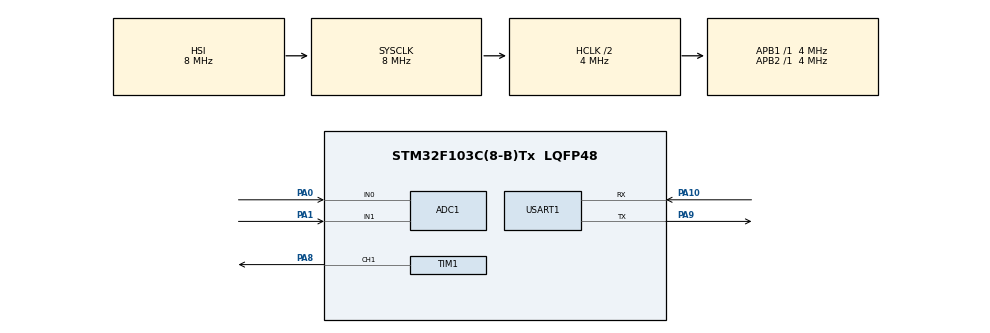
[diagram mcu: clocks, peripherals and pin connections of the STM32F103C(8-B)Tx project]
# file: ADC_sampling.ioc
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ADC1.Channel-7\#ChannelRegularConversion=ADC_CHANNEL_0
ADC1.Channel-8\#ChannelRegularConversion=ADC_CHANNEL_1
ADC1.Channel-9\#ChannelRegularConversion=ADC_CHANNEL_VREFINT
ADC1.ContinuousConvMode=DISABLE
ADC1.DataAlign=ADC_DATAALIGN_RIGHT
ADC1.DiscontinuousConvMode=DISABLE
ADC1.EnableRegularConversion=ENABLE
ADC1.InjNumberOfConversion=0
ADC1.NbrOfConversion=3
ADC1.NbrOfConversionFlag=1
ADC1.Rank-7\#ChannelRegularConversion=1
ADC1.Rank-8\#ChannelRegularConversion=2
ADC1.Rank-9\#ChannelRegularConversion=3
ADC1.SamplingTime-7\#ChannelRegularConversion=ADC_SAMPLETIME_1CYCLE_5
ADC1.SamplingTime-8\#ChannelRegularConversion=ADC_SAMPLETIME_1CYCLE_5
ADC1.SamplingTime-9\#ChannelRegularConversion=ADC_SAMPLETIME_1CYCLE_5
ADC1.ScanConvMode=ADC_SCAN_ENABLE
ADC1.master=1
Mcu.Family=STM32F1
Mcu.Name=STM32F103C(8-B)Tx
Mcu.Package=LQFP48
NVIC.PriorityGroup=NVIC_PRIORITYGROUP_4
NVIC.USART1_IRQn=true\:0\:0\:false\:false\:true\:true
PA0-WKUP.Signal=ADCx_IN0
PA1.Signal=ADCx_IN1
PA10.Mode=Asynchronous
PA10.Signal=USART1_RX
PA13.Mode=Serial_Wire
PA13.Signal=SYS_JTMS-SWDIO
PA14.Mode=Serial_Wire
PA14.Signal=SYS_JTCK-SWCLK
PA8.Signal=S_TIM1_CH1
PA9.Mode=Asynchronous
PA9.Signal=USART1_TX
ProjectManager.HeapSize=0x200
ProjectManager.StackSize=0x400
ProjectManager.TargetToolchain=EWARM
RCC.AHBCLKDivider=RCC_SYSCLK_DIV2
RCC.AHBFreq_Value=4000000
RCC.APB1Freq_Value=4000000
RCC.APB1TimFreq_Value=4000000
RCC.APB2Freq_Value=4000000
RCC.APB2TimFreq_Value=4000000
RCC.HCLKFreq_Value=4000000
RCC.PLLMUL=RCC_PLL_MUL12
RCC.SYSCLKFreq_VALUE=8000000
RCC.USBFreq_Value=48000000
SH.ADCx_IN0.0=ADC1_IN0,IN0
SH.ADCx_IN1.0=ADC1_IN1,IN1
SH.S_TIM1_CH1.0=TIM1_CH1,Output Compare1 CH1
TIM1.Channel-Output\ Compare1\ CH1=TIM_CHANNEL_1
TIM1.Period=10000
USART1.VirtualMode=VM_ASYNC
VP_ADC1_Vref_Input.Mode=IN-Vrefint
VP_TIM1_VS_ClockSourceINT.Mode=Internal
board=ADC_sampling

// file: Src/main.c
/**
  ******************************************************************************
  * File Name          : main.c
  * Description        : Main program body
  ******************************************************************************
  ** This notice applies to any and all portions of this file
  * that are not between comment pairs USER CODE BEGIN and
  * USER CODE END. Other portions of this file, whether
  * inserted by the user or by software development tools
  * are owned by their respective copyright owners.
  *
  * COPYRIGHT(c) 2017 STMicroelectronics
  *
  * Redistribution and use in source and binary forms, with or without modification,
  * are permitted provided that the following conditions are met:
  *   1. Redistributions of source code must retain the above copyright notice,
  *      this list of conditions and the following disclaimer.
  *   2. Redistributions in binary form must reproduce the above copyright notice,
  *      this list of conditions and the following disclaimer in the documentation
  *      and/or other materials provided with the distribution.
  *   3. Neither the name of STMicroelectronics nor the names of its contributors
  *      may be used to endorse or promote products derived from this software
  *      without specific prior written permission.
  *
  * THIS SOFTWARE IS PROVIDED BY THE COPYRIGHT HOLDERS AND CONTRIBUTORS "AS IS"
  * AND ANY EXPRESS OR IMPLIED WARRANTIES, INCLUDING, BUT NOT LIMITED TO, THE
  * IMPLIED WARRANTIES OF MERCHANTABILITY AND FITNESS FOR A PARTICULAR PURPOSE ARE
  * DISCLAIMED. IN NO EVENT SHALL THE COPYRIGHT HOLDER OR CONTRIBUTORS BE LIABLE
  * FOR ANY DIRECT, INDIRECT, INCIDENTAL, SPECIAL, EXEMPLARY, OR CONSEQUENTIAL
  * DAMAGES (INCLUDING, BUT NOT LIMITED TO, PROCUREMENT OF SUBSTITUTE GOODS OR
  * SERVICES; LOSS OF USE, DATA, OR PROFITS; OR BUSINESS INTERRUPTION) HOWEVER
  * CAUSED AND ON ANY THEORY OF LIABILITY, WHETHER IN CONTRACT, STRICT LIABILITY,
  * OR TORT (INCLUDING NEGLIGENCE OR OTHERWISE) ARISING IN ANY WAY OUT OF THE USE
  * OF THIS SOFTWARE, EVEN IF ADVISED OF THE POSSIBILITY OF SUCH DAMAGE.
  *
  ******************************************************************************
  */

#include "main.h"
#include "stm32f1xx_hal.h"

ADC_HandleTypeDef hadc1;

TIM_HandleTypeDef htim1;

UART_HandleTypeDef huart1;

/* USER CODE BEGIN PV */
/* Private variables ---------------------------------------------------------*/
#define ADC_BUFFER_SIZE 3
#define UART_TX_BUFFER_SIZE 7
uint32_t  aADCxConvertedValues[ADC_BUFFER_SIZE];
uint8_t uart_tx_buffer[UART_TX_BUFFER_SIZE];
uint8_t uart_rx_buffer;
uint16_t time_period = 100;
#define adc_no_of_conversions 3
uint32_t adc_channels_to_scan[adc_no_of_conversions] = {ADC_CHANNEL_0, ADC_CHANNEL_1, ADC_CHANNEL_VREFINT};
uint32_t adc_conversion_period = 1000;
uint32_t ch0_read, ch1_read;
uint8_t toggled = 0;

ADC_ChannelConfTypeDef sConfig;

/* USER CODE END PV */

void SystemClock_Config(void);
static void MX_GPIO_Init(void);
static void MX_ADC1_Init(void);
static void MX_USART1_UART_Init(void);
static void MX_TIM1_Init(void);

void HAL_TIM_MspPostInit(TIM_HandleTypeDef *htim);

/* USER CODE BEGIN PFP */
/* Private function prototypes -----------------------------------------------*/

/* USER CODE END PFP */

int main(void)
{

  /* MCU Configuration----------------------------------------------------------*/

  /* Reset of all peripherals, Initializes the Flash interface and the Systick. */
  HAL_Init();

  /* Configure the system clock */
  SystemClock_Config();

  /* Initialize all configured peripherals */
  MX_GPIO_Init();
  MX_ADC1_Init();
  MX_USART1_UART_Init();
  MX_TIM1_Init();

  /* USER CODE BEGIN 2 */

  /** Calibrating ADC */
  if (HAL_ADCEx_Calibration_Start(&hadc1) != HAL_OK) {
    /* Calibration Error */
    Error_Handler();
  }

  /** ADC start conversion */
  /* Start ADC conversion on regular group with transfer by DMA */

  uart_tx_buffer[0] = '{';
  uart_tx_buffer[3] = ',';
  uart_tx_buffer[6] = '}';
  /* USER CODE END 2 */

  /* Infinite loop */
  while (1)
  {

  /* USER CODE BEGIN 3 */
//   HAL_ADC_Start(&hadc1);
//    HAL_GPIO_TogglePin(GPIOC, GPIO_PIN_13);
    sConfig.Rank = 1;
    sConfig.SamplingTime = ADC_SAMPLETIME_1CYCLE_5;
    int i;
    for (i=0;i<adc_no_of_conversions;i++) {
      if (HAL_ADC_Init(&hadc1) != HAL_OK)
      {
        _Error_Handler(__FILE__, __LINE__);
      }
      sConfig.Channel = adc_channels_to_scan[i];
      if (HAL_ADC_ConfigChannel(&hadc1, &sConfig) != HAL_OK)
      {
        _Error_Handler(__FILE__, __LINE__);
      }

      HAL_ADC_Start(&hadc1);
      if (HAL_ADC_PollForConversion(&hadc1, 1000) == HAL_OK)
      {
          aADCxConvertedValues[i] = HAL_ADC_GetValue(&hadc1);
      }
      HAL_Delay(adc_conversion_period/adc_no_of_conversions);
      // ADC Deinit for stable readings of VRefInt
      HAL_ADC_DeInit(&hadc1);
    }
    ch0_read = (uint32_t)((1212.0 * ((double)aADCxConvertedValues[0]/ 1000.0) * 1250.0) / aADCxConvertedValues[2]);
    ch1_read = (uint32_t)((1212.0 * ((double)aADCxConvertedValues[1]/ 1000.0) * 1250.0) / aADCxConvertedValues[2]);

    if (ch0_read>4095) {ch0_read = 4095;}
    if (ch1_read>4095) {ch1_read = 4095;}

    uart_tx_buffer[1] = ch0_read >> 8;
    uart_tx_buffer[2] = ch0_read;
    uart_tx_buffer[4] = ch1_read >> 8;
    uart_tx_buffer[5] = ch1_read;

    if (toggled) {
      HAL_GPIO_TogglePin(GPIOC, GPIO_PIN_13);
      toggled = 0;
    }

    HAL_UART_Transmit(&huart1, &uart_tx_buffer[0], UART_TX_BUFFER_SIZE, 1000);
    HAL_UART_Receive_IT(&huart1, &uart_rx_buffer, 1);

//    if (ch0_read < 400 && !toggled) {
//      HAL_GPIO_TogglePin(GPIOC, GPIO_PIN_13/*, GPIO_PIN_SET*/);
//      toggled = 1;
//    } else if (ch0_read > 400 && toggled) {
//      HAL_GPIO_TogglePin(GPIOC, GPIO_PIN_13/*, GPIO_PIN_RESET*/);
//      toggled = 0;
//    }

  }
  /* USER CODE END 3 */

}

/** System Clock Configuration
*/
void SystemClock_Config(void)
{

  RCC_OscInitTypeDef RCC_OscInitStruct;
  RCC_ClkInitTypeDef RCC_ClkInitStruct;
  RCC_PeriphCLKInitTypeDef PeriphClkInit;

    /**Initializes the CPU, AHB and APB busses clocks
    */
  RCC_OscInitStruct.OscillatorType = RCC_OSCILLATORTYPE_HSI;
  RCC_OscInitStruct.HSIState = RCC_HSI_ON;
  RCC_OscInitStruct.HSICalibrationValue = 16;
  RCC_OscInitStruct.PLL.PLLState = RCC_PLL_NONE;
  if (HAL_RCC_OscConfig(&RCC_OscInitStruct) != HAL_OK)
  {
    _Error_Handler(__FILE__, __LINE__);
  }

    /**Initializes the CPU, AHB and APB busses clocks
    */
  RCC_ClkInitStruct.ClockType = RCC_CLOCKTYPE_HCLK|RCC_CLOCKTYPE_SYSCLK
                              |RCC_CLOCKTYPE_PCLK1|RCC_CLOCKTYPE_PCLK2;
  RCC_ClkInitStruct.SYSCLKSource = RCC_SYSCLKSOURCE_HSI;
  RCC_ClkInitStruct.AHBCLKDivider = RCC_SYSCLK_DIV2;
  RCC_ClkInitStruct.APB1CLKDivider = RCC_HCLK_DIV1;
  RCC_ClkInitStruct.APB2CLKDivider = RCC_HCLK_DIV1;

  if (HAL_RCC_ClockConfig(&RCC_ClkInitStruct, FLASH_LATENCY_0) != HAL_OK)
  {
    _Error_Handler(__FILE__, __LINE__);
  }

  PeriphClkInit.PeriphClockSelection = RCC_PERIPHCLK_ADC;
  PeriphClkInit.AdcClockSelection = RCC_ADCPCLK2_DIV2;
  if (HAL_RCCEx_PeriphCLKConfig(&PeriphClkInit) != HAL_OK)
  {
    _Error_Handler(__FILE__, __LINE__);
  }

    /**Configure the Systick interrupt time
    */
  HAL_SYSTICK_Config(HAL_RCC_GetHCLKFreq()/1000);

    /**Configure the Systick
    */
  HAL_SYSTICK_CLKSourceConfig(SYSTICK_CLKSOURCE_HCLK);

  /* SysTick_IRQn interrupt configuration */
  HAL_NVIC_SetPriority(SysTick_IRQn, 0, 0);
}

/* ADC1 init function */
static void MX_ADC1_Init(void)
{

//  ADC_ChannelConfTypeDef sConfig;

    /**Common config
    */
  hadc1.Instance = ADC1;
  hadc1.Init.ScanConvMode = ADC_SCAN_ENABLE;
  hadc1.Init.ContinuousConvMode = DISABLE;
  hadc1.Init.DiscontinuousConvMode = DISABLE;
  hadc1.Init.ExternalTrigConv = ADC_SOFTWARE_START;
  hadc1.Init.DataAlign = ADC_DATAALIGN_RIGHT;
  hadc1.Init.NbrOfConversion = 1;
  if (HAL_ADC_Init(&hadc1) != HAL_OK)
  {
    _Error_Handler(__FILE__, __LINE__);
  }

    /**Configure Regular Channel
    */
//  sConfig.Channel = ADC_CHANNEL_0;
//  sConfig.Rank = 1;
//  sConfig.SamplingTime = ADC_SAMPLETIME_1CYCLE_5;
//  if (HAL_ADC_ConfigChannel(&hadc1, &sConfig) != HAL_OK)
//  {
//    _Error_Handler(__FILE__, __LINE__);
//  }
//
//    /**Configure Regular Channel
//    */
//  sConfig.Channel = ADC_CHANNEL_1;
//  sConfig.Rank = 2;
//  if (HAL_ADC_ConfigChannel(&hadc1, &sConfig) != HAL_OK)
//  {
//    _Error_Handler(__FILE__, __LINE__);
//  }
//
//    /**Configure Regular Channel
//    */
//  sConfig.Channel = ADC_CHANNEL_VREFINT;
//  sConfig.Rank = 3;
//  if (HAL_ADC_ConfigChannel(&hadc1, &sConfig) != HAL_OK)
//  {
//    _Error_Handler(__FILE__, __LINE__);
//  }

}

/* TIM1 init function */
static void MX_TIM1_Init(void)
{

  TIM_ClockConfigTypeDef sClockSourceConfig;
  TIM_MasterConfigTypeDef sMasterConfig;
  TIM_OC_InitTypeDef sConfigOC;
  TIM_BreakDeadTimeConfigTypeDef sBreakDeadTimeConfig;

  htim1.Instance = TIM1;
  htim1.Init.Prescaler = 0;
  htim1.Init.CounterMode = TIM_COUNTERMODE_UP;
  htim1.Init.Period = 10000;
  htim1.Init.ClockDivision = TIM_CLOCKDIVISION_DIV1;
  htim1.Init.RepetitionCounter = 0;
  htim1.Init.AutoReloadPreload = TIM_AUTORELOAD_PRELOAD_DISABLE;
  if (HAL_TIM_Base_Init(&htim1) != HAL_OK)
  {
    _Error_Handler(__FILE__, __LINE__);
  }

  sClockSourceConfig.ClockSource = TIM_CLOCKSOURCE_INTERNAL;
  if (HAL_TIM_ConfigClockSource(&htim1, &sClockSourceConfig) != HAL_OK)
  {
    _Error_Handler(__FILE__, __LINE__);
  }

  if (HAL_TIM_OC_Init(&htim1) != HAL_OK)
  {
    _Error_Handler(__FILE__, __LINE__);
  }

  sMasterConfig.MasterOutputTrigger = TIM_TRGO_RESET;
  sMasterConfig.MasterSlaveMode = TIM_MASTERSLAVEMODE_DISABLE;
  if (HAL_TIMEx_MasterConfigSynchronization(&htim1, &sMasterConfig) != HAL_OK)
  {
    _Error_Handler(__FILE__, __LINE__);
  }

  sConfigOC.OCMode = TIM_OCMODE_TIMING;
  sConfigOC.Pulse = 0;
  sConfigOC.OCPolarity = TIM_OCPOLARITY_HIGH;
  sConfigOC.OCNPolarity = TIM_OCNPOLARITY_HIGH;
  sConfigOC.OCFastMode = TIM_OCFAST_DISABLE;
  sConfigOC.OCIdleState = TIM_OCIDLESTATE_RESET;
  sConfigOC.OCNIdleState = TIM_OCNIDLESTATE_RESET;
  if (HAL_TIM_OC_ConfigChannel(&htim1, &sConfigOC, TIM_CHANNEL_1) != HAL_OK)
  {
    _Error_Handler(__FILE__, __LINE__);
  }

  sBreakDeadTimeConfig.OffStateRunMode = TIM_OSSR_DISABLE;
  sBreakDeadTimeConfig.OffStateIDLEMode = TIM_OSSI_DISABLE;
  sBreakDeadTimeConfig.LockLevel = TIM_LOCKLEVEL_OFF;
  sBreakDeadTimeConfig.DeadTime = 0;
  sBreakDeadTimeConfig.BreakState = TIM_BREAK_DISABLE;
  sBreakDeadTimeConfig.BreakPolarity = TIM_BREAKPOLARITY_HIGH;
  sBreakDeadTimeConfig.AutomaticOutput = TIM_AUTOMATICOUTPUT_DISABLE;
  if (HAL_TIMEx_ConfigBreakDeadTime(&htim1, &sBreakDeadTimeConfig) != HAL_OK)
  {
    _Error_Handler(__FILE__, __LINE__);
  }

  HAL_TIM_MspPostInit(&htim1);

}

/* USART1 init function */
static void MX_USART1_UART_Init(void)
{

  huart1.Instance = USART1;
  huart1.Init.BaudRate = 115200;
  huart1.Init.WordLength = UART_WORDLENGTH_8B;
  huart1.Init.StopBits = UART_STOPBITS_1;
  huart1.Init.Parity = UART_PARITY_NONE;
  huart1.Init.Mode = UART_MODE_TX_RX;
  huart1.Init.HwFlowCtl = UART_HWCONTROL_NONE;
  huart1.Init.OverSampling = UART_OVERSAMPLING_16;
  if (HAL_UART_Init(&huart1) != HAL_OK)
  {
    _Error_Handler(__FILE__, __LINE__);
  }

}

/** Configure pins as
        * Analog
        * Input
        * Output
        * EVENT_OUT
        * EXTI
*/
static void MX_GPIO_Init(void)
{

  /* GPIO Ports Clock Enable */
  __HAL_RCC_GPIOA_CLK_ENABLE();
    GPIO_InitTypeDef GPIO_InitStruct;

  /* GPIO Ports Clock Enable */
  __HAL_RCC_GPIOC_CLK_ENABLE();

  /*Configure GPIO pin Output Level */
  HAL_GPIO_WritePin(GPIOC, GPIO_PIN_13, GPIO_PIN_RESET);

  /*Configure GPIO pin : PC14 */
  GPIO_InitStruct.Pin = GPIO_PIN_13;
  GPIO_InitStruct.Mode = GPIO_MODE_OUTPUT_PP;
  GPIO_InitStruct.Speed = GPIO_SPEED_FREQ_LOW;
  HAL_GPIO_Init(GPIOC, &GPIO_InitStruct);

}

void _Error_Handler(char * file, int line)
{
  while(1)
  {
  }
}

/************************ (C) COPYRIGHT STMicroelectronics *****END OF FILE****/
